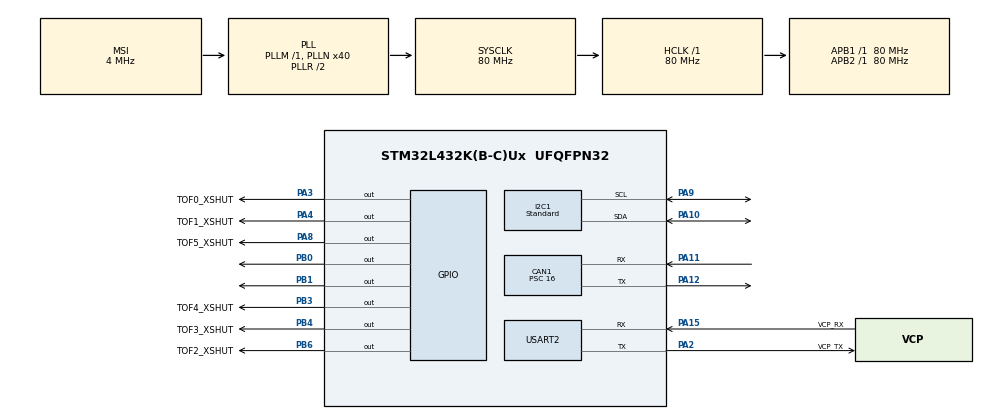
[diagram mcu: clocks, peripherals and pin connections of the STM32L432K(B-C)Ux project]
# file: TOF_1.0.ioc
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CAN1.BS1=CAN_BS1_8TQ
CAN1.BS2=CAN_BS2_2TQ
CAN1.CalculateBaudRate=454545
CAN1.CalculateTimeBit=2200
CAN1.CalculateTimeQuantum=200.0
CAN1.Prescaler=16
I2C1.I2C_Speed_Mode=I2C_Standard
I2C1.Speed=10
I2C1.Timing=0xF010F3FE
Mcu.Family=STM32L4
Mcu.Name=STM32L432K(B-C)Ux
Mcu.Package=UFQFPN32
NVIC.CAN1_RX0_IRQn=true\:0\:0\:false\:false\:true\:true\:true\:true
NVIC.CAN1_RX1_IRQn=true\:0\:0\:false\:false\:true\:true\:true\:true
NVIC.CAN1_SCE_IRQn=true\:0\:0\:false\:false\:true\:true\:true\:true
NVIC.CAN1_TX_IRQn=true\:0\:0\:false\:false\:true\:true\:true\:true
NVIC.I2C1_ER_IRQn=true\:0\:0\:false\:false\:true\:true\:true\:true
NVIC.I2C1_EV_IRQn=true\:0\:0\:false\:false\:true\:true\:true\:true
NVIC.PriorityGroup=NVIC_PRIORITYGROUP_4
PA0.GPIO_Label=MCO [High speed clock in]
PA0.Mode=HSE-External-Clock-Source-for-LittleOrca
PA0.Signal=RCC_CK_IN
PA10.GPIO_Pu=GPIO_PULLUP
PA10.Mode=I2C
PA10.Signal=I2C1_SDA
PA11.Mode=CAN_Activate
PA11.Signal=CAN1_RX
PA12.Mode=CAN_Activate
PA12.Signal=CAN1_TX
PA13\ (JTMS-SWDIO).GPIO_Label=SWDIO
PA13\ (JTMS-SWDIO).Mode=Serial_Wire
PA13\ (JTMS-SWDIO).Signal=SYS_JTMS-SWDIO
PA14\ (JTCK-SWCLK).GPIO_Label=SWCLK
PA14\ (JTCK-SWCLK).Mode=Serial_Wire
PA14\ (JTCK-SWCLK).Signal=SYS_JTCK-SWCLK
PA15\ (JTDI).GPIO_Label=VCP_RX
PA15\ (JTDI).Mode=Asynchronous
PA15\ (JTDI).Signal=USART2_RX
PA2.GPIO_Label=VCP_TX
PA2.Mode=Asynchronous
PA2.Signal=USART2_TX
PA3.GPIO_Label=TOF0_XSHUT
PA3.Signal=GPIO_Output
PA4.GPIO_Label=TOF1_XSHUT
PA4.Signal=GPIO_Output
PA8.GPIO_Label=TOF5_XSHUT
PA8.Signal=GPIO_Output
PA9.GPIO_Pu=GPIO_PULLUP
PA9.Mode=I2C
PA9.Signal=I2C1_SCL
PB0.GPIO_PuPd=GPIO_PULLDOWN
PB0.Signal=GPIO_Output
PB1.GPIO_PuPd=GPIO_PULLDOWN
PB1.Signal=GPIO_Output
PB3\ (JTDO-TRACESWO).GPIO_Label=TOF4_XSHUT
PB3\ (JTDO-TRACESWO).Signal=GPIO_Output
PB4\ (NJTRST).GPIO_Label=TOF3_XSHUT
PB4\ (NJTRST).Signal=GPIO_Output
PB6.GPIO_Label=TOF2_XSHUT
PB6.Signal=GPIO_Output
PC14-OSC32_IN\ (PC14).Mode=LSE-External-Oscillator
PC14-OSC32_IN\ (PC14).Signal=RCC_OSC32_IN
PC15-OSC32_OUT\ (PC15).Mode=LSE-External-Oscillator
PC15-OSC32_OUT\ (PC15).Signal=RCC_OSC32_OUT
ProjectManager.HeapSize=0x200
ProjectManager.StackSize=0x400
ProjectManager.TargetToolchain=STM32CubeIDE
RCC.AHBFreq_Value=80000000
RCC.APB1Freq_Value=80000000
RCC.APB1TimFreq_Value=80000000
RCC.APB2Freq_Value=80000000
RCC.APB2TimFreq_Value=80000000
RCC.CortexFreq_Value=80000000
RCC.HCLKFreq_Value=80000000
RCC.HSE_VALUE=8000000
RCC.HSI16_VALUE=16000000
RCC.HSI48_VALUE=48000000
RCC.HSI_VALUE=16000000
RCC.MSI_VALUE=4000000
RCC.PLLMUL=RCC_PLLMUL_4
RCC.PLLN=40
RCC.SYSCLKFreq_VALUE=80000000
RCC.SYSCLKSource=RCC_SYSCLKSOURCE_PLLCLK
RCC.VCOOutputFreq_Value=160000000
USART2.VirtualMode-Asynchronous=VM_ASYNC
board=NUCLEO-L432KC

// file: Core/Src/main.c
/* USER CODE BEGIN Header */
/**
  ******************************************************************************
  * @file           : main.c
  * @brief          : Main program body
  ******************************************************************************
  * @attention
  *
  * Copyright (c) 2022 STMicroelectronics.
  * All rights reserved.
  *
  * This software is licensed under terms that can be found in the LICENSE file
  * in the root directory of this software component.
  * If no LICENSE file comes with this software, it is provided AS-IS.
  *
  ******************************************************************************
  */
/* USER CODE END Header */
#include "main.h"

/* USER CODE BEGIN Includes */
#include <string.h>
#include <stdio.h>
#include "../../Drivers/VL53L0X/Platform/TOF.h"
#include "can.h"
/* USER CODE END Includes */

CAN_HandleTypeDef hcan1;

I2C_HandleTypeDef hi2c1;

UART_HandleTypeDef huart2;

void SystemClock_Config(void);
static void MX_GPIO_Init(void);
static void MX_USART2_UART_Init(void);
static void MX_I2C1_Init(void);
static void MX_CAN1_Init(void);

int main(void)
{

  /* MCU Configuration--------------------------------------------------------*/

  /* Reset of all peripherals, Initializes the Flash interface and the Systick. */
  HAL_Init();

  /* Configure the system clock */
  SystemClock_Config();

  /* Initialize all configured peripherals */
  MX_GPIO_Init();
  MX_USART2_UART_Init();
  MX_I2C1_Init();
  MX_CAN1_Init();
  /* USER CODE BEGIN 2 */
  configure_CAN(hcan1, CAN_ADDR_ODOMETRIE_TOF);

  /* USER CODE END 2 */

  /* Infinite loop */
  /* USER CODE BEGIN WHILE */
  char *data = {0x05};

  while (1)
  {
	send()
    /* USER CODE END WHILE */

  }
}

void SystemClock_Config(void)
{
  RCC_OscInitTypeDef RCC_OscInitStruct = {0};
  RCC_ClkInitTypeDef RCC_ClkInitStruct = {0};

  /** Configure the main internal regulator output voltage
  */
  if (HAL_PWREx_ControlVoltageScaling(PWR_REGULATOR_VOLTAGE_SCALE1) != HAL_OK)
  {
    Error_Handler();
  }

  /** Configure LSE Drive Capability
  */
  HAL_PWR_EnableBkUpAccess();
  __HAL_RCC_LSEDRIVE_CONFIG(RCC_LSEDRIVE_LOW);

  /** Initializes the RCC Oscillators according to the specified parameters
  * in the RCC_OscInitTypeDef structure.
  */
  RCC_OscInitStruct.OscillatorType = RCC_OSCILLATORTYPE_LSE|RCC_OSCILLATORTYPE_MSI;
  RCC_OscInitStruct.LSEState = RCC_LSE_ON;
  RCC_OscInitStruct.MSIState = RCC_MSI_ON;
  RCC_OscInitStruct.MSICalibrationValue = 0;
  RCC_OscInitStruct.MSIClockRange = RCC_MSIRANGE_6;
  RCC_OscInitStruct.PLL.PLLState = RCC_PLL_ON;
  RCC_OscInitStruct.PLL.PLLSource = RCC_PLLSOURCE_MSI;
  RCC_OscInitStruct.PLL.PLLM = 1;
  RCC_OscInitStruct.PLL.PLLN = 40;
  RCC_OscInitStruct.PLL.PLLP = RCC_PLLP_DIV7;
  RCC_OscInitStruct.PLL.PLLQ = RCC_PLLQ_DIV2;
  RCC_OscInitStruct.PLL.PLLR = RCC_PLLR_DIV2;
  if (HAL_RCC_OscConfig(&RCC_OscInitStruct) != HAL_OK)
  {
    Error_Handler();
  }

  /** Initializes the CPU, AHB and APB buses clocks
  */
  RCC_ClkInitStruct.ClockType = RCC_CLOCKTYPE_HCLK|RCC_CLOCKTYPE_SYSCLK
                              |RCC_CLOCKTYPE_PCLK1|RCC_CLOCKTYPE_PCLK2;
  RCC_ClkInitStruct.SYSCLKSource = RCC_SYSCLKSOURCE_PLLCLK;
  RCC_ClkInitStruct.AHBCLKDivider = RCC_SYSCLK_DIV1;
  RCC_ClkInitStruct.APB1CLKDivider = RCC_HCLK_DIV1;
  RCC_ClkInitStruct.APB2CLKDivider = RCC_HCLK_DIV1;

  if (HAL_RCC_ClockConfig(&RCC_ClkInitStruct, FLASH_LATENCY_4) != HAL_OK)
  {
    Error_Handler();
  }

  /** Enable MSI Auto calibration
  */
  HAL_RCCEx_EnableMSIPLLMode();
}

static void MX_CAN1_Init(void)
{

  hcan1.Instance = CAN1;
  hcan1.Init.Prescaler = 16;
  hcan1.Init.Mode = CAN_MODE_NORMAL;
  hcan1.Init.SyncJumpWidth = CAN_SJW_1TQ;
  hcan1.Init.TimeSeg1 = CAN_BS1_8TQ;
  hcan1.Init.TimeSeg2 = CAN_BS2_2TQ;
  hcan1.Init.TimeTriggeredMode = DISABLE;
  hcan1.Init.AutoBusOff = DISABLE;
  hcan1.Init.AutoWakeUp = DISABLE;
  hcan1.Init.AutoRetransmission = DISABLE;
  hcan1.Init.ReceiveFifoLocked = DISABLE;
  hcan1.Init.TransmitFifoPriority = DISABLE;
  if (HAL_CAN_Init(&hcan1) != HAL_OK)
  {
    Error_Handler();
  }

}

static void MX_I2C1_Init(void)
{

  hi2c1.Instance = I2C1;
  hi2c1.Init.Timing = 0xF010F3FE;
  hi2c1.Init.OwnAddress1 = 0;
  hi2c1.Init.AddressingMode = I2C_ADDRESSINGMODE_7BIT;
  hi2c1.Init.DualAddressMode = I2C_DUALADDRESS_DISABLE;
  hi2c1.Init.OwnAddress2 = 0;
  hi2c1.Init.OwnAddress2Masks = I2C_OA2_NOMASK;
  hi2c1.Init.GeneralCallMode = I2C_GENERALCALL_DISABLE;
  hi2c1.Init.NoStretchMode = I2C_NOSTRETCH_DISABLE;
  if (HAL_I2C_Init(&hi2c1) != HAL_OK)
  {
    Error_Handler();
  }

  /** Configure Analogue filter
  */
  if (HAL_I2CEx_ConfigAnalogFilter(&hi2c1, I2C_ANALOGFILTER_ENABLE) != HAL_OK)
  {
    Error_Handler();
  }

  /** Configure Digital filter
  */
  if (HAL_I2CEx_ConfigDigitalFilter(&hi2c1, 0) != HAL_OK)
  {
    Error_Handler();
  }

}

static void MX_USART2_UART_Init(void)
{

  huart2.Instance = USART2;
  huart2.Init.BaudRate = 115200;
  huart2.Init.WordLength = UART_WORDLENGTH_8B;
  huart2.Init.StopBits = UART_STOPBITS_1;
  huart2.Init.Parity = UART_PARITY_NONE;
  huart2.Init.Mode = UART_MODE_TX_RX;
  huart2.Init.HwFlowCtl = UART_HWCONTROL_NONE;
  huart2.Init.OverSampling = UART_OVERSAMPLING_16;
  huart2.Init.OneBitSampling = UART_ONE_BIT_SAMPLE_DISABLE;
  huart2.AdvancedInit.AdvFeatureInit = UART_ADVFEATURE_NO_INIT;
  if (HAL_UART_Init(&huart2) != HAL_OK)
  {
    Error_Handler();
  }

}

static void MX_GPIO_Init(void)
{
  GPIO_InitTypeDef GPIO_InitStruct = {0};

  /* GPIO Ports Clock Enable */
  __HAL_RCC_GPIOC_CLK_ENABLE();
  __HAL_RCC_GPIOA_CLK_ENABLE();
  __HAL_RCC_GPIOB_CLK_ENABLE();

  /*Configure GPIO pin Output Level */
  HAL_GPIO_WritePin(GPIOA, TOF0_XSHUT_Pin|TOF1_XSHUT_Pin|TOF5_XSHUT_Pin, GPIO_PIN_RESET);

  /*Configure GPIO pin Output Level */
  HAL_GPIO_WritePin(GPIOB, GPIO_PIN_0|GPIO_PIN_1|TOF4_XSHUT_Pin|TOF3_XSHUT_Pin
                          |TOF2_XSHUT_Pin, GPIO_PIN_RESET);

  /*Configure GPIO pins : TOF0_XSHUT_Pin TOF1_XSHUT_Pin TOF5_XSHUT_Pin */
  GPIO_InitStruct.Pin = TOF0_XSHUT_Pin|TOF1_XSHUT_Pin|TOF5_XSHUT_Pin;
  GPIO_InitStruct.Mode = GPIO_MODE_OUTPUT_PP;
  GPIO_InitStruct.Pull = GPIO_NOPULL;
  GPIO_InitStruct.Speed = GPIO_SPEED_FREQ_LOW;
  HAL_GPIO_Init(GPIOA, &GPIO_InitStruct);

  /*Configure GPIO pins : PB0 PB1 */
  GPIO_InitStruct.Pin = GPIO_PIN_0|GPIO_PIN_1;
  GPIO_InitStruct.Mode = GPIO_MODE_OUTPUT_PP;
  GPIO_InitStruct.Pull = GPIO_PULLDOWN;
  GPIO_InitStruct.Speed = GPIO_SPEED_FREQ_LOW;
  HAL_GPIO_Init(GPIOB, &GPIO_InitStruct);

  /*Configure GPIO pins : TOF4_XSHUT_Pin TOF3_XSHUT_Pin TOF2_XSHUT_Pin */
  GPIO_InitStruct.Pin = TOF4_XSHUT_Pin|TOF3_XSHUT_Pin|TOF2_XSHUT_Pin;
  GPIO_InitStruct.Mode = GPIO_MODE_OUTPUT_PP;
  GPIO_InitStruct.Pull = GPIO_NOPULL;
  GPIO_InitStruct.Speed = GPIO_SPEED_FREQ_LOW;
  HAL_GPIO_Init(GPIOB, &GPIO_InitStruct);

}

void Error_Handler(void)
{
  __disable_irq();
  while (1)
  {
  }
}
